VERSION ""

NS_ :

BS_:

BU_: ECU1 ECU2

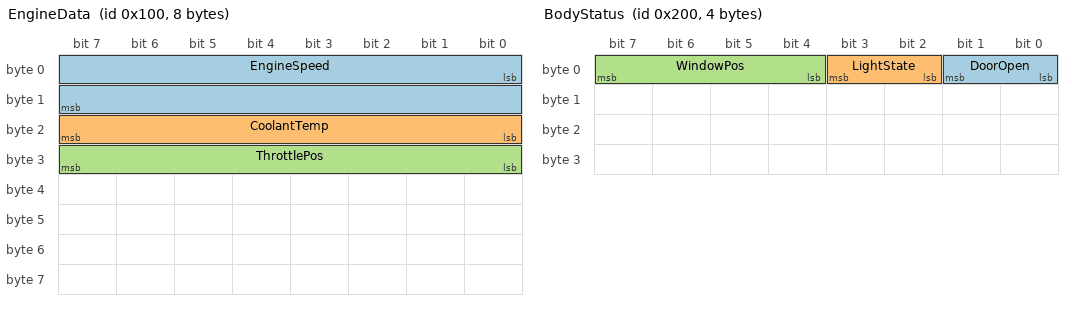
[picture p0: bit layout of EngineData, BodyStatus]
BO_ 256 EngineData: 8 ECU1
 SG_ EngineSpeed : 0|16@1+ (1,0) [0|8000] "rpm" Vector__XXX
 SG_ CoolantTemp : 16|8@1+ (0.5,-40) [-40|215] "°C" Vector__XXX
 SG_ ThrottlePos : 24|8@1+ (0.4,0) [0|100] "%" Vector__XXX

BO_ 512 BodyStatus: 4 ECU2
 SG_ DoorOpen : 0|2@1+ (1,0) [0|3] "" Vector__XXX
 SG_ LightState : 2|2@1+ (1,0) [0|3] "" Vector__XXX
 SG_ WindowPos : 4|4@1+ (10,0) [0|100] "%" Vector__XXX

BO_ 1024 Diagnostics: 8 ECU1
 SG_ DTC_Code : 0|24@1+ (1,0) [0|16777215] "" Vector__XXX
 SG_ MIL_Status : 24|2@1+ (1,0) [0|3] "" Vector__XXX

VAL_ 512 DoorOpen 0 "Closed" 1 "Open" 2 "Ajar" 3 "Unknown";
VAL_ 512 LightState 0 "Off" 1 "On" 2 "Auto" 3 "Unknown";

CM_ SG_ 256 EngineSpeed "Engine rotational speed in RPM";
CM_ SG_ 256 CoolantTemp "Engine coolant temperature";
CM_ SG_ 512 DoorOpen "Current door status";
BA_DEF_ "BusType" STRING ;
BA_DEF_DEF_ "BusType" "CAN";
